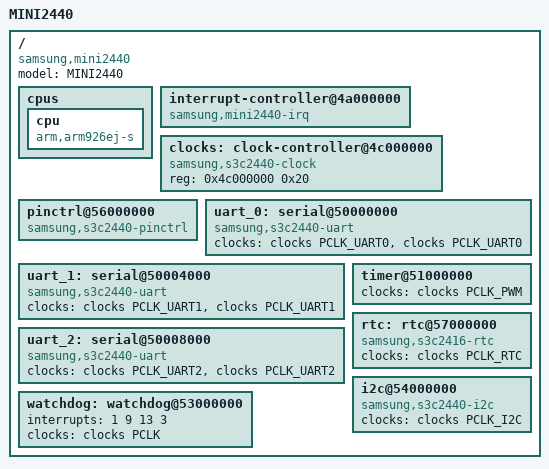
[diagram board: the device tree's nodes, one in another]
// SPDX-License-Identifier: GPL-2.0
/*
 * Samsung's S3C2416 SoC device tree source
 *
 * Copyright (c) 2013 Heiko Stuebner <heiko@sntech.de>
 */

#include <dt-bindings/clock/s3c2410.h>
#include "s3c24xx.dtsi"
#include "mini2440-pinctrl.dtsi"

/ {
	model = "MINI2440";
	compatible = "samsung,mini2440";

	cpus {
		cpu {
			compatible = "arm,arm926ej-s";
		};
	};

	interrupt-controller@4a000000 {
		compatible = "samsung,mini2440-irq";
	};

	clocks: clock-controller@4c000000 {
		compatible = "samsung,s3c2440-clock";
		reg = <0x4c000000 0x20>;
		#clock-cells = <1>;
	};

	pinctrl@56000000 {
		compatible = "samsung,s3c2440-pinctrl";
	};
	
	uart_0: serial@50000000 {
		compatible = "samsung,s3c2440-uart";
		clock-names = "uart", "clk_uart_baud2";
		clocks = <&clocks PCLK_UART0>, <&clocks PCLK_UART0>;
		//pinctrl-names = "default";
		//pinctrl-0 = <&uart0_data>, <&uart0_fctl>;
		status = "okay";
	};

	uart_1: serial@50004000 {
		compatible = "samsung,s3c2440-uart";
		clock-names = "uart", "clk_uart_baud2";
		clocks = <&clocks PCLK_UART1>, <&clocks PCLK_UART1>;
		//pinctrl-names = "default";
		//pinctrl-0 = <&uart1_data>, <&uart1_fctl>;
		status = "okay";
	};

	uart_2: serial@50008000 {
		compatible = "samsung,s3c2440-uart";
		clock-names = "uart", "clk_uart_baud2";
		clocks = <&clocks PCLK_UART2>, <&clocks PCLK_UART2>;
		status = "okay";
	};

	timer@51000000 {
		clocks = <&clocks PCLK_PWM>;
		clock-names = "timers";
	};

	watchdog: watchdog@53000000 {
		interrupts = <1 9 13 3>;
		clocks = <&clocks PCLK>;
		clock-names = "watchdog";
		status = "okay";
	};

	rtc: rtc@57000000 {
		compatible = "samsung,s3c2416-rtc";
		clocks = <&clocks PCLK_RTC>;
		clock-names = "rtc";
		status = "okay";
	};

	i2c@54000000 {
		compatible = "samsung,s3c2440-i2c";
		clocks = <&clocks PCLK_I2C>;
		clock-names = "i2c";
	};
};
